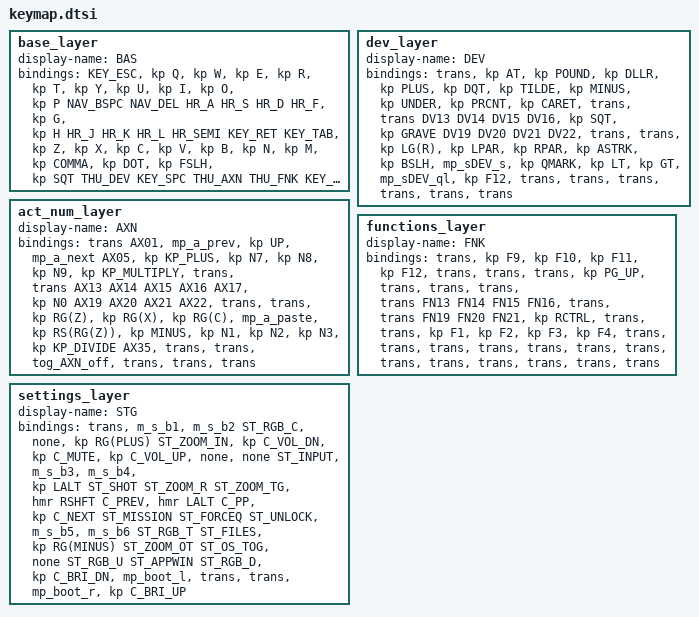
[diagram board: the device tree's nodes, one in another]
/* The five shared typing layers.
 *
 * Written once and used on both OSes. MAC-CANONICAL throughout: the primary
 * shortcut modifier is Command (LGUI), so macOS needs no host configuration
 * at all. The Windows machines carry a Win/Ctrl remap instead, which makes
 * a firmware LGUI arrive as Control there.
 *
 * Anything genuinely Windows-specific lives on the WIN overlay layers in
 * os/windows/keymap.dtsi -- do not add OS branches here.
 *
 * &trans means "this layer doesn't change this key" and falls through to
 * whatever is active below, which is ultimately BAS. The outer columns
 * (ESC, BSPC, DEL, RET, TAB) and the thumbs are bound once on BAS and
 * inherited everywhere. Only put a real binding above BAS where the layer
 * genuinely differs -- and use &none, not &trans, where a layer wants a
 * key to do nothing, or it will fall through to a letter.
 */

        base_layer {
            /* The only layer that binds the outer columns and thumbs. */
            display-name = "BAS";
            bindings = <
    KEY_ESC  &kp Q  &kp W  &kp E  &kp R  &kp T        &kp Y  &kp U      &kp I    &kp O     &kp P  NAV_BSPC
    NAV_DEL   HR_A   HR_S   HR_D   HR_F  &kp G        &kp H   HR_J       HR_K     HR_L   HR_SEMI   KEY_RET
    KEY_TAB  &kp Z  &kp X  &kp C  &kp V  &kp B        &kp N  &kp M  &kp COMMA  &kp DOT  &kp FSLH   &kp SQT
                        THU_DEV  KEY_SPC  THU_AXN     THU_FNK  KEY_SPC  THU_STG
            >;
        };

        dev_layer {
            #define DV13  &hml  LCTRL  AMPS
            #define DV14  &hml  LGUI   LBRC
            #define DV15  &hml  LALT   RBRC
            #define DV16  &hml  LSHFT  EQUAL
            #define DV19  &hmr  RSHFT  EXCL
            #define DV20  &hmr  LALT   LBKT
            #define DV21  &hmr  RGUI   RBKT
            #define DV22  &hmr  RCTRL  PIPE

            display-name = "DEV";
            bindings = <
    &trans     &kp AT  &kp POUND  &kp DLLR  &kp PLUS   &kp DQT        &kp TILDE  &kp MINUS  &kp UNDER  &kp PRCNT    &kp CARET   &trans
    &trans       DV13       DV14      DV15      DV16   &kp SQT        &kp GRAVE       DV19       DV20       DV21         DV22   &trans
    &trans  &kp LG(R)  &kp LPAR  &kp RPAR  &kp ASTRK  &kp BSLH       &mp_sDEV_s  &kp QMARK     &kp LT     &kp GT  &mp_sDEV_ql  &kp F12
                            &trans  &trans  &trans        &trans  &trans  &trans
            >;
        };

        act_num_layer {
            /* Left hand navigation and clipboard, right hand numpad.
             * Fully shared -- there is no Windows overlay for this layer.
             *
             * Several keys happen to work on both OSes without help:
             *   - Option/Alt+Shift+arrows extends selection by word on the
             *     Mac and expands selection in VS Code on Windows.
             *   - Redo is Shift+Cmd+Z, which arrives as Shift+Ctrl+Z on
             *     Windows and is accepted there as redo.
             *   - Position 35 carries both Cmd and Ctrl, so the remap is a
             *     no-op and it stays Win+Ctrl+D (new virtual desktop) on
             *     Windows.
             */
            #define AX01  &kp  LA(LS(RIGHT))         // extend selection right
            #define AX05  &kp  LG(F)                 // find
            #define AX13  &hml LCTRL LA(LS(LEFT))    // extend selection left
            #define AX14  &hml LGUI  LEFT
            #define AX15  &hml LALT  DOWN
            #define AX16  &hml LSHFT RIGHT
            #define AX17  &kp  LA(LG(F))             // replace (Opt+Cmd+F)
            #define AX19  &hmr LSHFT N4
            #define AX20  &hmr LALT  N5
            #define AX21  &hmr RGUI  N6
            #define AX22  &hmr RCTRL EQUAL
            #define AX35  &kp  LC(LG(D))             // new virtual desktop (windows)

            display-name = "AXN";
            bindings = <
    &trans       AX01  &mp_a_prev     &kp UP    &mp_a_next          AX05        &kp KP_PLUS  &kp N7  &kp N8  &kp N9  &kp KP_MULTIPLY  &trans
    &trans       AX13        AX14       AX15         AX16          AX17             &kp N0    AX19    AX20    AX21             AX22  &trans
    &trans  &kp RG(Z)   &kp RG(X)  &kp RG(C)  &mp_a_paste  &kp RS(RG(Z))         &kp MINUS  &kp N1  &kp N2  &kp N3    &kp KP_DIVIDE    AX35
                            &trans  &trans  &tog_AXN_off        &trans  &trans  &trans
            >;
        };

        functions_layer {
            /* Sparse on purpose, and &trans rather than &none throughout,
             * so holding FNK over a latched AXN composes -- F-keys on the
             * left, numpad still live on the right. */
            #define FN13  &hml LCTRL F5
            #define FN14  &hml LGUI  F6
            #define FN15  &hml LALT  F7
            #define FN16  &hml LSHFT F8
            #define FN19  &hmr RSHFT HOME
            #define FN20  &hmr LALT  PG_DN
            #define FN21  &hmr RGUI  END

            display-name = "FNK";
            bindings = <
    &trans  &kp F9  &kp F10  &kp F11  &kp F12  &trans        &trans  &trans  &kp PG_UP  &trans     &trans  &trans
    &trans    FN13     FN14     FN15     FN16  &trans        &trans    FN19       FN20    FN21  &kp RCTRL  &trans
    &trans  &kp F1   &kp F2   &kp F3   &kp F4  &trans        &trans  &trans     &trans  &trans     &trans  &trans
                            &trans  &trans  &trans        &trans  &trans  &trans
            >;
        };

        settings_layer {
            /* macOS side, since macOS is the default. Windows replaces ten
             * of these positions via WIN_STG; the rest it inherits.
             *
             * Volume, mute and the media keys live here and only here.
             * They are OS-independent HID consumer codes, so duplicating
             * them per OS gained nothing and previously left one OS with no
             * media keys at all.
             *
             * &none rather than &trans where macOS has no equivalent --
             * &trans here would fall through to BAS and type a letter. */
            #define ST_UNLOCK  &mp_sSTG_cb           // tap: studio unlock | shift: clear profile | alt: clear all
            #define ST_SHOT    &mp_sSTG_screenshot
            #define ST_ZOOM_R  &mp_a_zoom_reset      // tap: zoom reset | shift: zoom reset (vscode)
            #define ST_RGB_C   &mp_sSTG_rgb_c
            #define ST_RGB_T   &mp_sSTG_rgb_t
            #define ST_RGB_U   &mp_sSTG_rgb_u
            #define ST_RGB_D   &mp_sSTG_rgb_d

            #define ST_ZOOM_IN  &kp LA(LG(EQUAL))    // accessibility zoom in
            #define ST_ZOOM_TG  &kp LA(LG(N8))       // accessibility zoom toggle
            #define ST_ZOOM_OT  &kp LA(LG(MINUS))    // accessibility zoom out
            #define ST_FORCEQ   &kp LA(LG(ESC))      // force quit  | win: task manager
            #define ST_MISSION  &kp LC(UP)           // mission control | win: system info
            #define ST_APPWIN   &kp LC(DOWN)         // application windows | win: security
            #define ST_INPUT    &kp LC(SPACE)        // input source -- works on both
            #define ST_FILES    &mp_sSTG_f           // finder | win: file explorer

            /* OS mode toggle, decoupled from the bluetooth profile.
             *
             * The profile macros set the OS as a side effect, which is fine
             * on BLE but leaves two gaps: connecting over USB doesn't touch
             * the profile, and deep-sleep wake resets layer state so the
             * flag is lost while the profile survives. Either way you'd
             * otherwise have to re-tap a BT key and reassign the radio just
             * to fix the OS mode.
             *
             * Self-inverse by fall-through: WIN_STG is &trans at this
             * position, so pressing it in Windows mode lands on this same
             * binding and toggles WIN back off. Positions 31 and 32 are the
             * only ones free on STG *and* transparent on WIN_STG, which is
             * what makes the trick work here. */
            #define ST_OS_TOG   &tog WIN             // macOS <-> Windows mode

            display-name = "STG";
            bindings = <
       &trans  &m_s_b1  &m_s_b2  ST_RGB_C     &none   &kp RG(PLUS)       ST_ZOOM_IN  &kp C_VOL_DN         &kp C_MUTE  &kp C_VOL_UP      &none       &none
     ST_INPUT  &m_s_b3  &m_s_b4  &kp LALT   ST_SHOT      ST_ZOOM_R       ST_ZOOM_TG  &hmr RSHFT C_PREV  &hmr LALT C_PP  &kp C_NEXT  ST_MISSION   ST_FORCEQ
    ST_UNLOCK  &m_s_b5  &m_s_b6  ST_RGB_T  ST_FILES  &kp RG(MINUS)       ST_ZOOM_OT     ST_OS_TOG             &none    ST_RGB_U    ST_APPWIN    ST_RGB_D
                     &kp C_BRI_DN  &mp_boot_l  &trans        &trans  &mp_boot_r  &kp C_BRI_UP
            >;
        };
